# H616 register map
Vendor: Allwinner; Series: H616; File version: 0.1
CPU: other 0, little endian, MPU, no FPU, 0 interrupt priority bits
Registers are 32-bit, read-write, reset 0x0 unless marked. A register's access mark holds for its fields unless they carry their own. Offsets are from the block's base; [hi:lo] are bit positions; 'fields as' and 'values as' point back to an identical list.

## SYS_CFG
Base 0x03000000
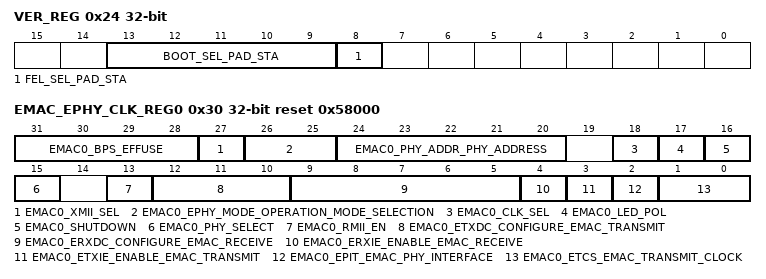
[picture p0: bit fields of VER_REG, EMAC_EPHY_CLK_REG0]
0x24 VER_REG reset not defined — Version Register
  [13:9] BOOT_SEL_PAD_STA ro — Bit[9] Bit[10] Bit[11] Bit[12] Bit[13] Media 1 1 1 1 1 MLC NAND 0 1 1 1 1 SLC NAND 1 0 1 1 1 eMMC USER 1 1 0 1 1 eMMC_BOOT 1 1 1 0 1 SPI_NOR 1 1 1 1 0 SPI_NAND Bit[9] --> BOOT SELECT0 ( For H616 package, Bit[9] is fixed at 1 ) Bit[10] --> PC3 Bit[11] --> PC4 Bit[12] --> PC5 Bit[13] --> PC6
  [8] FEL_SEL_PAD_STA ro — Fel_Select_Pin_Status 0: Run_FEL 1:Try Media Boot
    0=Run_FEL; 1=Try (Try Media Boot)
0x30 EMAC_EPHY_CLK_REG0 reset 0x58000 — EMAC-EPHY Clock Register 0
  [31:28] EMAC0_BPS_EFFUSE
  [27] EMAC0_XMII_SEL — EMAC0 XMII_SEL 0: Internal SMI and MII 1: External SMI and MII
    0=Internal SMI and MII; 1=External SMI and MII
  [26:25] EMAC0_EPHY_MODE_OPERATION_MODE_SELECTION — EMAC0 EPHY_MODE Operation Mode Selection 00 : Normal Mode 01 : Sim Mode 10 : AFE Test Mode 11 : /
  [24:20] EMAC0_PHY_ADDR_PHY_ADDRESS
  [18] EMAC0_CLK_SEL — EMAC0 CLK_SEL 0 : 25 MHz 1 : 24 MHz
  [17] EMAC0_LED_POL — EMAC0 LED_POL 0 : High active 1 : Low active
  [16] EMAC0_SHUTDOWN — EMAC0 SHUTDOWN 0 : Power up 1 : Shutdown
  [15] EMAC0_PHY_SELECT — EMAC0 PHY_SELECT 0 : External PHY 1 : Internal PHY
  [13] EMAC0_RMII_EN — EMAC0 RMII_EN 0 : Disable RMII Module 1 : Enable RMII Module When this bit is asserted, MII or RGMII interface is disabled( This means bit13 is prior to bit2)
  [12:10] EMAC0_ETXDC_CONFIGURE_EMAC_TRANSMIT — EMAC0 ETXDC Configure EMAC Transmit Clock Delay Chain
  [9:5] EMAC0_ERXDC_CONFIGURE_EMAC_RECEIVE — EMAC0 ERXDC Configure EMAC Receive Clock Delay Chain
  [4] EMAC0_ERXIE_ENABLE_EMAC_RECEIVE — EMAC0 ERXIE Enable EMAC Receive Clock Invertor 0: Disable 1: Enable
    0=Disable; 1=Enable
  [3] EMAC0_ETXIE_ENABLE_EMAC_TRANSMIT — EMAC0 ETXIE Enable EMAC Transmit Clock Invertor 0: Disable 1: Enable
    0=Disable; 1=Enable
  [2] EMAC0_EPIT_EMAC_PHY_INTERFACE — EMAC0 EPIT EMAC PHY Interface Type 0: MII 1: RGMII
    0=MII; 1=RGMII
  [1:0] EMAC0_ETCS_EMAC_TRANSMIT_CLOCK — EMAC0 ETCS EMAC Transmit Clock Source 00: Transmit clock source for MII 01: External transmit clock source for GMII and RGMII 10: Internal transmit clock source for GMII and RGMII 11: Reserved
    0=Transmit clock source for MII; 1=External transmit clock source for GMII and RGMII; 2=Internal transmit clock source for GMII and RGMII

## LRADC
Base 0x05070800
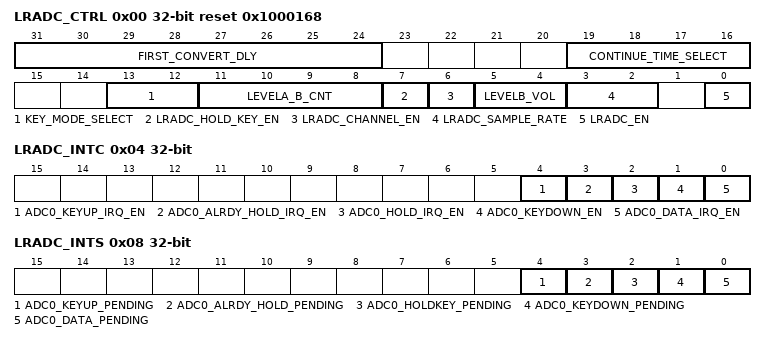
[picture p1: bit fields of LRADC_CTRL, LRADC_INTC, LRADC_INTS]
0x00 LRADC_CTRL reset 0x1000168 — LRADC Control Register
  [31:24] FIRST_CONVERT_DLY — ADC First Convert Delay Setting ADC conversion is delayed by n samples.
  [19:16] CONTINUE_TIME_SELECT — Continue Mode Time Select One of 8*(N+1) sample as a valuable sample data.
  [13:12] KEY_MODE_SELECT — Key Mode Select 00: Normal Mode 01: Single Mode 10: Continue Mode
    0=Normal Mode; 1=Single Mode; 2=Continue Mode
  [11:8] LEVELA_B_CNT — Level A to Level B time threshold select, judge ADC convert value in level A to level B in n+1 samples.
  [7] LRADC_HOLD_KEY_EN — LRADC Hold KEY Enable 0: Disable 1: Enable
    0=Disable; 1=Enable
  [6] LRADC_CHANNEL_EN — LRADC Channel Enable 0: Disable 1: Enable
    0=Disable; 1=Enable
  [5:4] LEVELB_VOL — Level B Corresponding Data Value Setting (the real voltage value) 00: 0x3C (1.266 V) 01: 0x39 (1.202 V) 10: 0x36 (1.139 V) 11: 0x33 (1.076 V)
    0=0x3C (1.266 V); 1=0x39 (1.202 V); 2=0x36 (1.139 V); 3=0x33 (1.076 V)
  [3:2] LRADC_SAMPLE_RATE — LRADC Sample Rate 00: 2 kHz 01: 1 kHz 10: 500 Hz 11: 250 Hz
    0=_2_kHz; 1=_1_kHz; 2=500 Hz; 3=250 Hz
  [0] LRADC_EN — LRADC Enable 0: Disable 1: Enable
    0=Disable; 1=Enable
0x04 LRADC_INTC — LRADC Interrupt Control Register
  [all] fields
    0=Disable; 1=Enable
  [4] ADC0_KEYUP_IRQ_EN — ADC0 Key Up IRQ Enable 0: Disable 1: Enable
  [3] ADC0_ALRDY_HOLD_IRQ_EN — ADC0 Already Hold Key IRQ Enable 0: Disable 1: Enable
  [2] ADC0_HOLD_IRQ_EN — ADC0 Hold Key IRQ Enable 0: Disable 1: Enable
  [1] ADC0_KEYDOWN_EN — ADC0 Key Down Enable 0: Disable 1: Enable
  [0] ADC0_DATA_IRQ_EN — ADC0 Data IRQ Enable 0: Disable 1: Enable
0x08 LRADC_INTS — LRADC Interrupt Status Register
  [4] ADC0_KEYUP_PENDING write-1-clears — ADC0 Key up Pending Bit When general key is pulled up, and the corresponding interrupt is enabled, the status bit is set. 0: No IRQ 1: IRQ Pending Writing 1 to the bit will clear it and its corresponding interrupt if the interrupt is enabled.
    0=No_IRQ; 1=IRQ (IRQ Pending Writing 1 to the bit will clear it and its corresponding interrupt if the interrupt is enabled.)
  [3] ADC0_ALRDY_HOLD_PENDING write-1-clears — ADC0 Already Hold Pending Bit When hold key is pulled down and the general key is pulled down, and the corresponding interrupt is enabled. 0: No IRQ 1: IRQ Pending Writing 1 to the bit will clear it and its corresponding interrupt if the interrupt is enabled.
    values as ADC0_KEYUP_PENDING
  [2] ADC0_HOLDKEY_PENDING write-1-clears — ADC0 Hold Key Pending Bit When hold key is pulled down, and the corresponding interrupt is enabled, the status bit is set and the interrupt line is set. 0: NO IRQ 1: IRQ Pending Writing 1 to the bit will clear it and its corresponding interrupt if the interrupt is enabled.
    0=NO_IRQ; 1=IRQ (IRQ Pending Writing 1 to the bit will clear it and its corresponding interrupt if the interrupt is enabled.)
  [1] ADC0_KEYDOWN_PENDING write-1-clears — ADC0 Key Down IRQ Pending Bit When general key is pulled down, and the corresponding interrupt is enabled, the status bit is set and the interrupt line is set. 0: No IRQ 1: IRQ Pending Writing 1 to the bit will clear it and its corresponding interrupt if the interrupt is enabled.
    values as ADC0_KEYUP_PENDING
  [0] ADC0_DATA_PENDING write-1-clears — ADC0 Data IRQ Pending Bit 0: No IRQ 1: IRQ Pending Writing 1 to the bit will clear it and its corresponding interrupt if the interrupt is enabled.
    values as ADC0_KEYUP_PENDING
0x0C LRADC_DATA0 reset 0x3F — LRADC Data Register0
  [5:0] LRADC0_DATA ro
